# csr register map
Vendor: litex
Litex SoC 2023-04-13 10:41:22
Registers are 32-bit, read-write, reset 0x0 unless marked. A register's access mark holds for its fields unless they carry their own. Offsets are from the block's base; lines under a group give offsets from that group; [hi:lo] are bit positions; {n}, {i} and the like mark numbered series; 'fields as' and 'values as' point back to an identical list; <NAME> marks a mode.

## Memory map
0xF0000000 SPI1 size 0x1C
0xF0000800 LEDS size 0x4
0xF0001000 CTRL size 0xC
0xF0001800 ETHMAC size 0x44
0xF0002000 ETHPHY size 0x10
0xF0002800 I2C0 size 0x8
0xF0003000 IDENTIFIER_MEM size 0x4
0xF0003800 SDRAM size 0x1C
0xF0004000 TIMER0 size 0x2C
0xF0004800 UART size 0x20

## Interrupts
0 uart (UART)
1 timer0 (TIMER0)
2 ethmac (ETHMAC)

## Further device data
memoryRegions:
  ROM baseAddress=0x00000000 size=0x00009000
  SRAM baseAddress=0x10000000 size=0x00002000
  MAIN_RAM baseAddress=0x40000000 size=0x00800000
  ETHMAC baseAddress=0x80000000 size=0x00002000
  CSR baseAddress=0xF0000000 size=0x00010000
constants:
  CONFIG_CLOCK_FREQUENCY value=100000000
  CONFIG_CPU_HAS_INTERRUPT value=None
  CONFIG_CPU_RESET_ADDR value=0
  CONFIG_CPU_HAS_DCACHE value=None
  CONFIG_CPU_HAS_ICACHE value=None
  CONFIG_CPU_TYPE_VEXRISCV value=None
  CONFIG_CPU_VARIANT_STANDARD value=None
  CONFIG_CPU_HUMAN_NAME value=VexRiscv
  CONFIG_CPU_NOP value=nop
  CONFIG_WITH_BUILD_TIME value=None
  CONFIG_L2_SIZE value=8192
  CONFIG_CSR_DATA_WIDTH value=32
  CONFIG_CSR_ALIGNMENT value=32
  CONFIG_BUS_STANDARD value=WISHBONE
  CONFIG_BUS_DATA_WIDTH value=32
  CONFIG_BUS_ADDRESS_WIDTH value=32
  CONFIG_BUS_BURSTING value=0
  ETHMAC_RX_SLOTS value=2
  ETHMAC_TX_SLOTS value=2
  ETHMAC_SLOT_SIZE value=2048
  ETHMAC_INTERRUPT value=2
  TIMER0_INTERRUPT value=1
  UART_INTERRUPT value=0
  CONFIG_HAS_I2C value=None

## SPI1
Base 0xF0000000
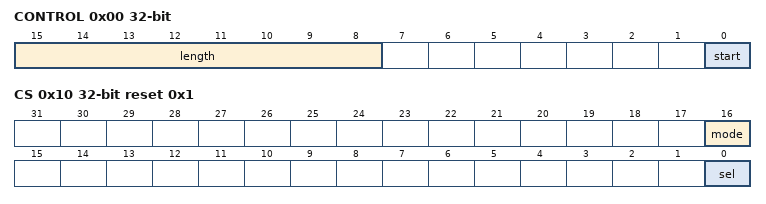
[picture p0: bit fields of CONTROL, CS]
0x00 CONTROL — SPI Control.
  [15:8] length — SPI Xfer Length (in bits).
  [0] start — SPI Xfer Start (Write ``1`` to start Xfer).
0x04 STATUS — SPI Status.
  [0] done — SPI Xfer Done (when read as ``1``).
0x08 MOSI — SPI MOSI data (MSB-first serialization).
  [7:0] mosi
0x0C MISO — SPI MISO data (MSB-first de-serialization).
  [7:0] miso
0x10 CS reset 0x1 — SPI CS Chip-Select and Mode.
  [16] mode, [0] sel
0x14 LOOPBACK — SPI Loopback Mode.
  [0] mode
0x18 CLK_DIVIDER reset 0xD — SPI Clk Divider.
  [15:0] clk_divider

## LEDS
Base 0xF0000800
0x00 OUT — GPIO Output(s) Control.
  [0] out

## CTRL
Base 0xF0001000
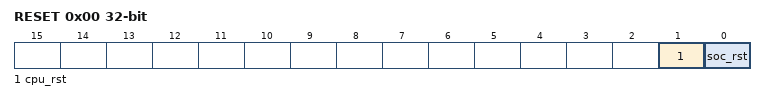
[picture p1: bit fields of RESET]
0x00 RESET
  [1] cpu_rst — Write `1` to this register to reset the CPU(s) of the SoC (Hold Reset)
  [0] soc_rst — Write `1` to this register to reset the full SoC (Pulse Reset)
0x04 SCRATCH reset 0x12345678 — Use this register as a scratch space to verify that software read/write accesses to the Wishbone/CSR bus are working correctly. The initial reset value of 0x1234578 can be used to verify endianness.
0x08 BUS_ERRORS — Total number of Wishbone bus errors (timeouts) since start.

## ETHMAC
Base 0xF0001800
0x00 SRAM_WRITER_SLOT
  [0] sram_writer_slot
0x04 SRAM_WRITER_LENGTH
  [10:0] sram_writer_length
0x08 SRAM_WRITER_ERRORS
0x0C SRAM_WRITER_EV_STATUS — This register contains the current raw level of the available event trigger. Writes to this register have no effect.
  [0] available — Level of the ``available`` event
0x10 SRAM_WRITER_EV_PENDING — When a available event occurs, the corresponding bit will be set in this register. To clear the Event, set the corresponding bit in this register.
  [0] available — `1` if a `available` event occurred. This Event is **level triggered** when the signal is **high**.
0x14 SRAM_WRITER_EV_ENABLE — This register enables the corresponding available events. Write a ``0`` to this register to disable individual events.
  [0] available — Write a ``1`` to enable the ``available`` Event
0x18 SRAM_READER_START
  [0] sram_reader_start
0x1C SRAM_READER_READY
  [0] sram_reader_ready
0x20 SRAM_READER_LEVEL
  [1:0] sram_reader_level
0x24 SRAM_READER_SLOT
  [0] sram_reader_slot
0x28 SRAM_READER_LENGTH
  [10:0] sram_reader_length
0x2C SRAM_READER_EV_STATUS — This register contains the current raw level of the event0 event trigger. Writes to this register have no effect.
  [0] event0 — Level of the ``event0`` event
0x30 SRAM_READER_EV_PENDING — When a event0 event occurs, the corresponding bit will be set in this register. To clear the Event, set the corresponding bit in this register.
  [0] event0 — `1` if a this particular event occurred. This Event is triggered on a **rising** edge.
0x34 SRAM_READER_EV_ENABLE — This register enables the corresponding event0 events. Write a ``0`` to this register to disable individual events.
  [0] event0 — Write a ``1`` to enable the ``event0`` Event
0x38 PREAMBLE_CRC reset 0x1
  [0] preamble_crc
0x3C RX_DATAPATH_PREAMBLE_ERRORS
0x40 RX_DATAPATH_CRC_ERRORS
